VERSION ""

NS_ :

BS_:

BU_: XXX X

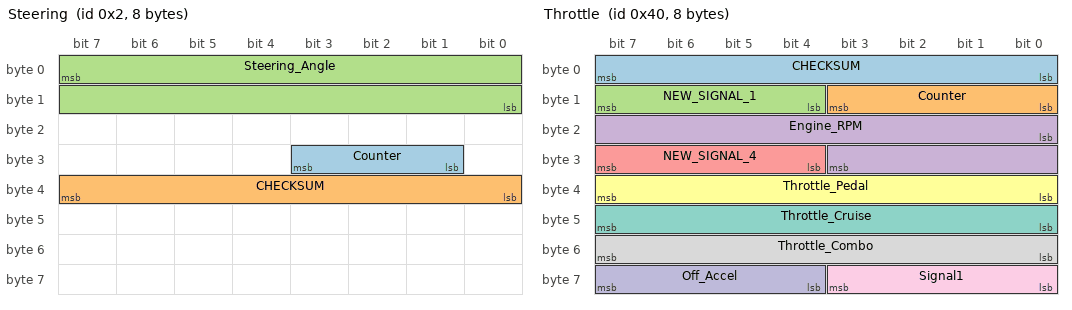
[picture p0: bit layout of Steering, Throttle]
BO_ 2 Steering: 8 XXX
 SG_ Counter : 25|3@1+ (1,0) [0|7] "" XXX
 SG_ CHECKSUM : 32|8@1+ (1,0) [0|255] "" XXX
 SG_ Steering_Angle : 7|16@0- (0.1,0) [0|65535] "" XXX

BO_ 64 Throttle: 8 XXX
 SG_ CHECKSUM : 0|8@1+ (1,0) [0|255] "" XXX
 SG_ Counter : 8|4@1+ (1,0) [0|255] "" XXX
 SG_ NEW_SIGNAL_1 : 12|4@1+ (1,0) [0|1] "" XXX
 SG_ Engine_RPM : 16|12@1+ (1,0) [0|255] "" XXX
 SG_ NEW_SIGNAL_4 : 28|4@1+ (1,0) [0|1] "" XXX
 SG_ Throttle_Pedal : 32|8@1+ (1,0) [0|255] "" XXX
 SG_ Throttle_Cruise : 40|8@1+ (1,0) [0|255] "" XXX
 SG_ Throttle_Combo : 48|8@1+ (1,0) [0|1] "" XXX
 SG_ Signal1 : 56|4@1+ (1,0) [0|255] "" XXX
 SG_ Off_Accel : 60|4@1+ (1,0) [0|7] "" XXX

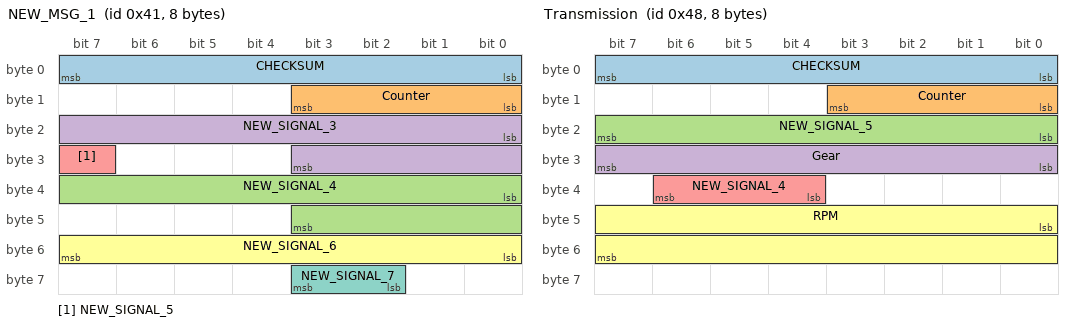
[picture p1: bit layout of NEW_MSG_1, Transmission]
BO_ 65 NEW_MSG_1: 8 XXX
 SG_ CHECKSUM : 0|8@1+ (1,0) [0|255] "" XXX
 SG_ Counter : 8|4@1+ (1,0) [0|15] "" XXX
 SG_ NEW_SIGNAL_4 : 32|12@1+ (1,0) [0|255] "" XXX
 SG_ NEW_SIGNAL_3 : 16|12@1+ (1,0) [0|1] "" XXX
 SG_ NEW_SIGNAL_5 : 31|1@0+ (1,0) [0|15] "" XXX
 SG_ NEW_SIGNAL_6 : 48|8@1+ (1,0) [0|63] "" XXX
 SG_ NEW_SIGNAL_7 : 59|2@0+ (1,0) [0|255] "" XXX

BO_ 72 Transmission: 8 XXX
 SG_ CHECKSUM : 0|8@1+ (1,0) [0|255] "" XXX
 SG_ Counter : 8|4@1+ (1,0) [0|15] "" XXX
 SG_ NEW_SIGNAL_5 : 16|8@1+ (1,0) [0|255] "" XXX
 SG_ Gear : 24|8@1+ (1,0) [0|255] "" XXX
 SG_ NEW_SIGNAL_4 : 38|3@0+ (1,0) [0|255] "" XXX
 SG_ RPM : 40|16@1+ (1,0) [0|255] "" XXX

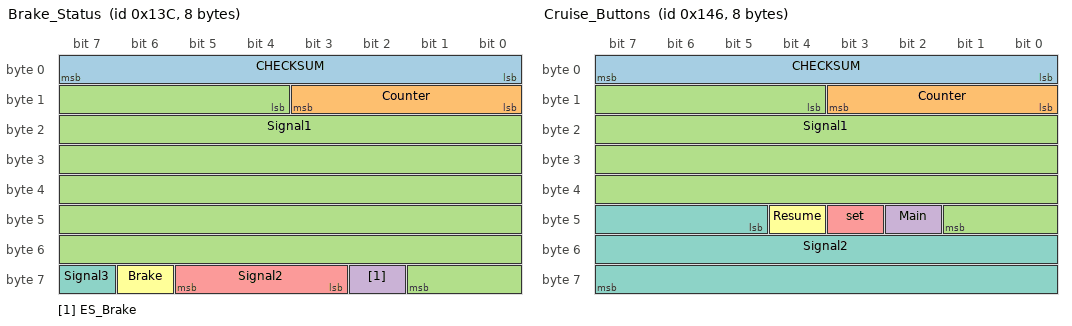
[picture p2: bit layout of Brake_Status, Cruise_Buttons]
BO_ 316 Brake_Status: 8 XXX
 SG_ CHECKSUM : 0|8@1+ (1,0) [0|1] "" XXX
 SG_ Counter : 8|4@1+ (1,0) [0|1] "" XXX
 SG_ Signal1 : 12|46@1+ (1,0) [0|1] "" XXX
 SG_ ES_Brake : 58|1@1+ (1,0) [0|1] "" XXX
 SG_ Signal2 : 59|3@1+ (1,0) [0|1] "" XXX
 SG_ Brake : 62|1@1+ (1,0) [0|1] "" XXX
 SG_ Signal3 : 63|1@1+ (1,0) [0|1] "" XXX

BO_ 326 Cruise_Buttons: 8 XXX
 SG_ CHECKSUM : 0|8@1+ (1,0) [0|255] "" XXX
 SG_ Counter : 8|4@1+ (1,0) [0|15] "" XXX
 SG_ Signal1 : 12|30@1+ (1,0) [0|1073741823] "" XXX
 SG_ Main : 42|1@1+ (1,0) [0|1] "" XXX
 SG_ set : 43|1@1+ (1,0) [0|1] "" XXX
 SG_ Resume : 44|1@1+ (1,0) [0|1] "" XXX
 SG_ Signal2 : 45|19@1+ (1,0) [0|524287] "" XXX

BO_ 315 G_Sensor: 8 XXX
 SG_ Longitudinal : 56|8@1- (-0.1,0) [0|255] "m/s2" XXX
 SG_ Lateral : 48|8@1- (-0.1,0) [0|255] "m/s2" XXX

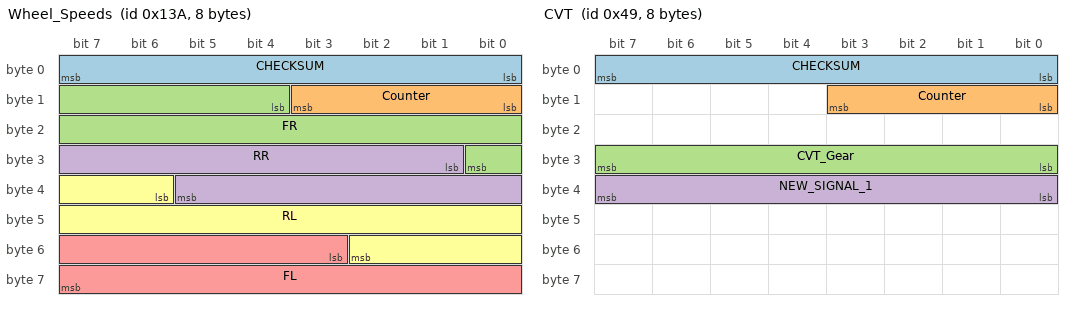
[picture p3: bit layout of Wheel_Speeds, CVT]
BO_ 314 Wheel_Speeds: 8 XXX
 SG_ CHECKSUM : 0|8@1+ (1,0) [0|255] "" XXX
 SG_ Counter : 8|4@1+ (1,0) [0|15] "" XXX
 SG_ FR : 12|13@1+ (0.057,0) [0|255] "kph" XXX
 SG_ RR : 25|13@1+ (0.057,0) [0|255] "kph" XXX
 SG_ FL : 51|13@1+ (0.057,0) [0|255] "kph" XXX
 SG_ RL : 38|13@1+ (0.057,0) [0|255] "kph" XXX

BO_ 73 CVT: 8 XXX
 SG_ CHECKSUM : 0|8@1+ (1,0) [0|255] "" XXX
 SG_ Counter : 8|4@1+ (1,0) [0|15] "" XXX
 SG_ CVT_Gear : 24|8@1+ (1,0) [0|127] "" XXX
 SG_ NEW_SIGNAL_1 : 32|8@1+ (1,0) [0|4095] "" XXX

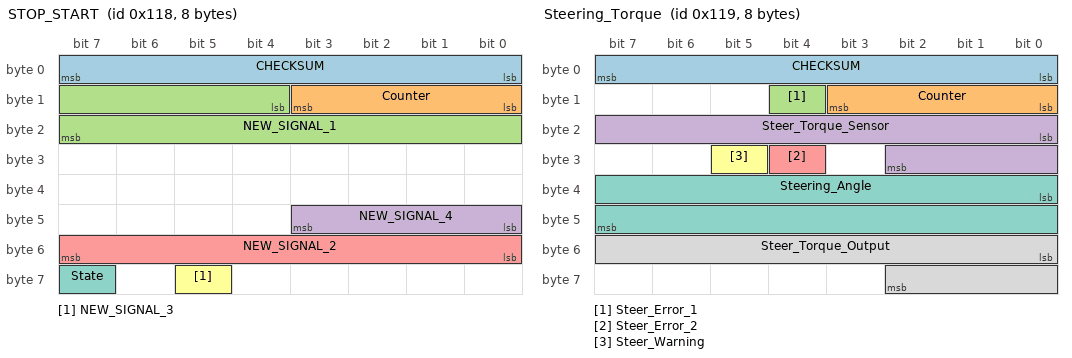
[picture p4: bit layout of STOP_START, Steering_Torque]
BO_ 280 STOP_START: 8 XXX
 SG_ CHECKSUM : 0|8@1+ (1,0) [0|1] "" XXX
 SG_ Counter : 8|4@1+ (1,0) [0|1] "" XXX
 SG_ NEW_SIGNAL_1 : 12|12@1- (1,0) [0|4095] "" XXX
 SG_ NEW_SIGNAL_4 : 40|4@1+ (1,0) [0|255] "" XXX
 SG_ NEW_SIGNAL_2 : 48|8@1- (1,0) [0|255] "" XXX
 SG_ NEW_SIGNAL_3 : 61|1@1+ (1,0) [0|7] "" XXX
 SG_ State : 63|1@1+ (1,0) [0|1] "" XXX

BO_ 281 Steering_Torque: 8 XXX
 SG_ CHECKSUM : 0|8@1+ (1,0) [0|3] "" XXX
 SG_ Counter : 8|4@1+ (1,0) [0|15] "" XXX
 SG_ Steer_Error_1 : 12|1@0+ (1,0) [0|7] "" XXX
 SG_ Steer_Torque_Sensor : 16|11@1- (-1,0) [0|3] "" XXX
 SG_ Steer_Error_2 : 28|1@1+ (1,0) [0|3] "" XXX
 SG_ Steer_Warning : 29|1@1+ (1,0) [0|1] "" XXX
 SG_ Steering_Angle : 32|16@1- (-0.0217,0) [0|255] "" X
 SG_ Steer_Torque_Output : 48|11@1- (-1,0) [0|31] "" XXX

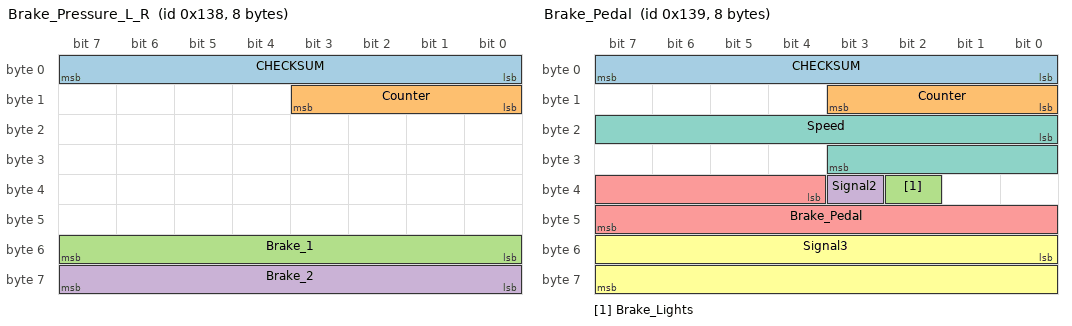
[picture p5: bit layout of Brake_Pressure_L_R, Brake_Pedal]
BO_ 312 Brake_Pressure_L_R: 8 XXX
 SG_ CHECKSUM : 0|8@1+ (1,0) [0|31] "" XXX
 SG_ Counter : 8|4@1+ (1,0) [0|3] "" XXX
 SG_ Brake_1 : 48|8@1+ (1,0) [0|255] "" XXX
 SG_ Brake_2 : 56|8@1+ (1,0) [0|255] "" XXX

BO_ 313 Brake_Pedal: 8 XXX
 SG_ CHECKSUM : 0|8@1+ (1,0) [0|1] "" XXX
 SG_ Counter : 8|4@1+ (1,0) [0|1] "" XXX
 SG_ Brake_Lights : 34|1@1+ (1,0) [0|7] "" XXX
 SG_ Signal2 : 35|1@1+ (1,0) [0|1] "" XXX
 SG_ Brake_Pedal : 36|12@1+ (1,0) [0|65535] "" XXX
 SG_ Signal3 : 48|16@1+ (1,0) [0|1] "" XXX
 SG_ Speed : 16|12@1+ (0.05625,0) [0|255] "kph" XXX

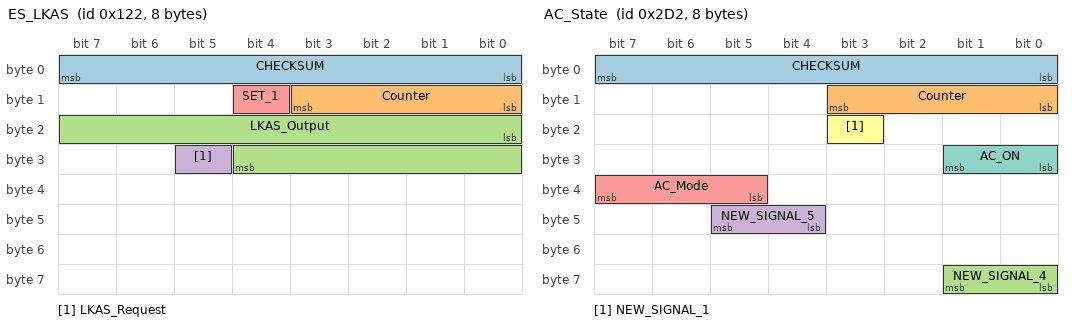
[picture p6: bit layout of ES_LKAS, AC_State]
BO_ 290 ES_LKAS: 8 XXX
 SG_ CHECKSUM : 0|8@1+ (1,0) [0|255] "" XXX
 SG_ Counter : 8|4@1+ (1,0) [0|15] "" XXX
 SG_ LKAS_Output : 16|13@1- (-1,0) [0|3] "" XXX
 SG_ LKAS_Request : 29|1@0+ (1,0) [0|3] "" XXX
 SG_ SET_1 : 12|1@0+ (1,0) [0|3] "" XXX

BO_ 722 AC_State: 8 XXX
 SG_ CHECKSUM : 0|8@1+ (1,0) [0|255] "" XXX
 SG_ Counter : 8|4@1+ (1,0) [0|15] "" XXX
 SG_ NEW_SIGNAL_4 : 56|2@1+ (1,0) [0|3] "" XXX
 SG_ NEW_SIGNAL_5 : 45|2@0+ (1,0) [0|3] "" XXX
 SG_ AC_Mode : 37|3@1+ (1,0) [0|1] "" XXX
 SG_ NEW_SIGNAL_1 : 19|1@1+ (1,0) [0|1] "" XXX
 SG_ AC_ON : 24|2@1+ (1,0) [0|1] "" XXX

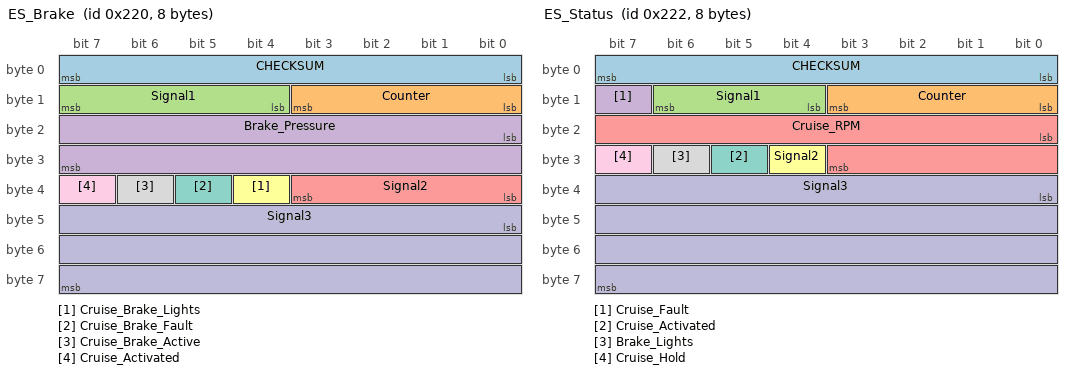
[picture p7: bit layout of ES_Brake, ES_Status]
BO_ 544 ES_Brake: 8 XXX
 SG_ CHECKSUM : 0|8@1+ (1,0) [0|255] "" XXX
 SG_ Counter : 8|4@1+ (1,0) [0|15] "" XXX
 SG_ Signal1 : 12|4@1+ (1,0) [0|1] "" XXX
 SG_ Brake_Pressure : 16|16@1+ (1,0) [0|255] "" XXX
 SG_ Signal2 : 32|4@1+ (1,0) [0|1] "" XXX
 SG_ Cruise_Brake_Lights : 36|1@1+ (1,0) [0|63] "" XXX
 SG_ Cruise_Brake_Fault : 37|1@1+ (1,0) [0|1] "" XXX
 SG_ Cruise_Brake_Active : 38|1@1+ (1,0) [0|1] "" XXX
 SG_ Cruise_Activated : 39|1@1+ (1,0) [0|1] "" XXX
 SG_ Signal3 : 40|24@1+ (1,0) [0|1] "" XXX

BO_ 545 ES_Distance: 8 XXX
 SG_ CHECKSUM : 0|8@1+ (1,0) [0|255] "" XXX
 SG_ Counter : 8|4@1+ (1,0) [0|15] "" XXX
 SG_ Signal1 : 12|3@1+ (1,0) [0|1] "" XXX
 SG_ Cruise_Fault : 15|1@1+ (1,0) [0|1] "" XXX
 SG_ Cruise_Throttle : 16|12@1+ (1,0) [0|15] "" XXX
 SG_ Signal2 : 28|4@1+ (1,0) [0|1] "" XXX
 SG_ Car_Follow : 32|1@1+ (1,0) [0|1] "" XXX
 SG_ Signal3 : 33|3@1+ (1,0) [0|1] "" XXX
 SG_ Cruise_Brake_Active : 36|1@1+ (1,0) [0|1] "" XXX
 SG_ Distance_Swap : 37|1@1+ (1,0) [0|15] "" XXX
 SG_ Cruise_EPB : 38|1@1+ (1,0) [0|1] "" XXX
 SG_ Signal4 : 39|1@0+ (1,0) [0|1] "" XXX
 SG_ Close_Distance : 40|8@1+ (1,0) [0|1] "" XXX
 SG_ Signal5 : 48|8@1+ (1,0) [0|1] "" XXX
 SG_ Cruise_Cancel : 56|1@1+ (1,0) [0|1] "" XXX
 SG_ Cruise_Set : 57|1@1+ (1,0) [0|1] "" XXX
 SG_ Cruise_Resume : 58|1@1+ (1,0) [0|1] "" XXX
 SG_ Signal6 : 59|5@1+ (1,0) [0|1] "" XXX

BO_ 546 ES_Status: 8 XXX
 SG_ CHECKSUM : 0|8@1+ (1,0) [0|255] "" XXX
 SG_ Counter : 8|4@1+ (1,0) [0|15] "" XXX
 SG_ Signal1 : 12|3@1+ (1,0) [0|1] "" XXX
 SG_ Cruise_Fault : 15|1@1+ (1,0) [0|1] "" XXX
 SG_ Cruise_RPM : 16|12@1+ (1,0) [0|255] "" XXX
 SG_ Signal2 : 28|1@0+ (1,0) [0|1] "" XXX
 SG_ Cruise_Activated : 29|1@0+ (1,0) [0|3] "" XXX
 SG_ Brake_Lights : 30|1@1+ (1,0) [0|3] "" XXX
 SG_ Cruise_Hold : 31|1@1+ (1,0) [0|1] "" XXX
 SG_ Signal3 : 32|32@1+ (1,0) [0|1] "" XXX

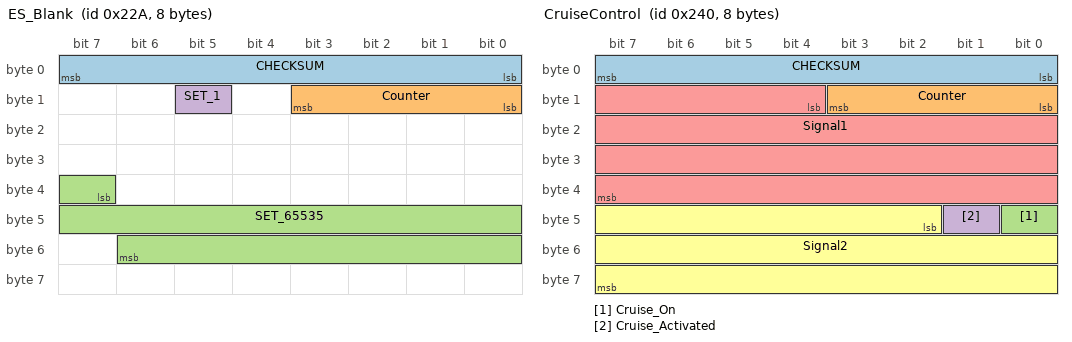
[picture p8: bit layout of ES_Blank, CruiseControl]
BO_ 554 ES_Blank: 8 XXX
 SG_ CHECKSUM : 0|8@1+ (1,0) [0|255] "" XXX
 SG_ Counter : 8|4@1+ (1,0) [0|15] "" XXX
 SG_ SET_65535 : 39|16@1+ (1,0) [0|16777215] "" XXX
 SG_ SET_1 : 13|1@1+ (1,0) [0|7] "" XXX

BO_ 557 NEW_MSG_14: 8 XXX
 SG_ CHECKSUM : 0|8@1+ (1,0) [0|255] "" XXX
 SG_ Counter : 8|4@1+ (1,0) [0|15] "" XXX

BO_ 576 CruiseControl: 8 XXX
 SG_ CHECKSUM : 0|8@1+ (1,0) [0|255] "" XXX
 SG_ Counter : 8|4@1+ (1,0) [0|15] "" XXX
 SG_ Cruise_On : 40|1@1+ (1,0) [0|3] "" XXX
 SG_ Cruise_Activated : 41|1@1+ (1,0) [0|3] "" XXX
 SG_ Signal1 : 12|28@1+ (1,0) [0|1] "" XXX
 SG_ Signal2 : 42|22@1+ (1,0) [0|3] "" XXX

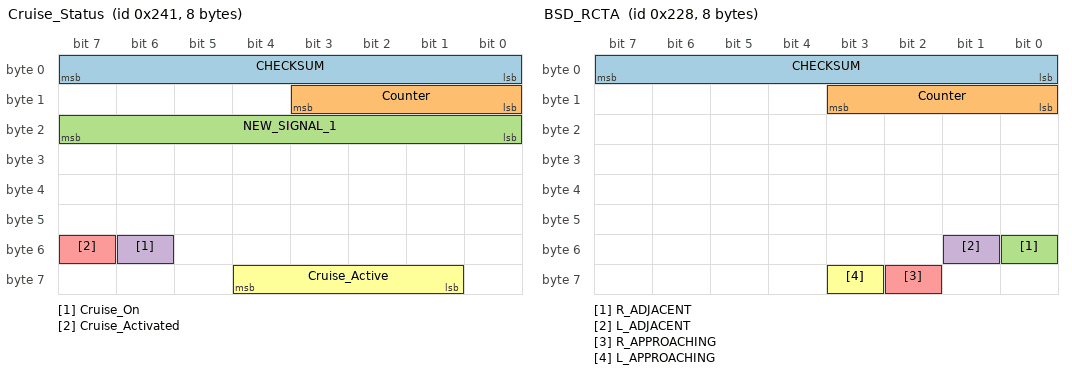
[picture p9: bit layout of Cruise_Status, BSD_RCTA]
BO_ 577 Cruise_Status: 8 XXX
 SG_ CHECKSUM : 0|8@1+ (1,0) [0|255] "" XXX
 SG_ Counter : 8|4@1+ (1,0) [0|15] "" XXX
 SG_ NEW_SIGNAL_1 : 16|8@1+ (1,0) [0|255] "" XXX
 SG_ Cruise_On : 54|1@1+ (1,0) [0|1] "" XXX
 SG_ Cruise_Activated : 55|1@1+ (1,0) [0|1] "" XXX
 SG_ Cruise_Active : 57|4@1+ (1,0) [0|1] "" XXX

BO_ 552 BSD_RCTA: 8 XXX
 SG_ CHECKSUM : 0|8@1+ (1,0) [0|255] "" XXX
 SG_ Counter : 8|4@1+ (1,0) [0|15] "" XXX
 SG_ R_ADJACENT : 48|1@1+ (1,0) [0|1] "" XXX
 SG_ L_ADJACENT : 49|1@1+ (1,0) [0|1] "" XXX
 SG_ R_APPROACHING : 58|1@1+ (1,0) [0|1] "" XXX
 SG_ L_APPROACHING : 59|1@1+ (1,0) [0|1] "" XXX

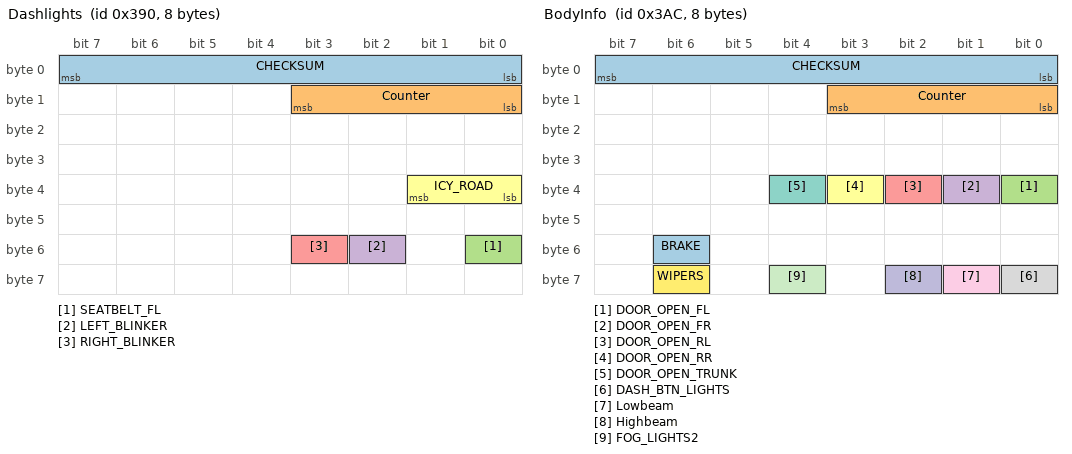
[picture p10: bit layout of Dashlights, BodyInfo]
BO_ 912 Dashlights: 8 XXX
 SG_ CHECKSUM : 0|8@1+ (1,0) [0|255] "" XXX
 SG_ Counter : 8|4@1+ (1,0) [0|15] "" XXX
 SG_ SEATBELT_FL : 48|1@1+ (1,0) [0|1] "" XXX
 SG_ LEFT_BLINKER : 50|1@1+ (1,0) [0|3] "" XXX
 SG_ RIGHT_BLINKER : 51|1@1+ (1,0) [0|1] "" XXX
 SG_ ICY_ROAD : 32|2@1+ (1,0) [0|3] "" XXX

BO_ 940 BodyInfo: 8 XXX
 SG_ CHECKSUM : 0|8@1+ (1,0) [0|1] "" XXX
 SG_ Counter : 8|4@1+ (1,0) [0|1] "" XXX
 SG_ DOOR_OPEN_FL : 32|1@1+ (1,0) [0|255] "" XXX
 SG_ DOOR_OPEN_FR : 33|1@1+ (1,0) [0|3] "" XXX
 SG_ DOOR_OPEN_RL : 34|1@1+ (1,0) [0|1] "" XXX
 SG_ DOOR_OPEN_RR : 35|1@1+ (1,0) [0|1] "" XXX
 SG_ DOOR_OPEN_TRUNK : 36|1@0+ (1,0) [0|1] "" XXX
 SG_ DASH_BTN_LIGHTS : 56|1@0+ (1,0) [0|1] "" XXX
 SG_ Lowbeam : 57|1@1+ (1,0) [0|3] "" XXX
 SG_ Highbeam : 58|1@1+ (1,0) [0|1] "" XXX
 SG_ FOG_LIGHTS2 : 60|1@1+ (1,0) [0|1] "" XXX
 SG_ WIPERS : 62|1@0+ (1,0) [0|1] "" XXX
 SG_ BRAKE : 54|1@1+ (1,0) [0|1] "" XXX

BO_ 801 ES_DashStatus: 8 XXX
 SG_ CHECKSUM : 0|8@1+ (1,0) [0|255] "" XXX
 SG_ Counter : 8|4@1+ (1,0) [0|7] "" XXX
 SG_ PCB_Off : 12|1@1+ (1,0) [0|1] "" XXX
 SG_ LDW_Off : 13|1@1+ (1,0) [0|1] "" XXX
 SG_ Signal1 : 14|10@1+ (1,0) [0|1] "" XXX
 SG_ Cruise_Soft_Disable : 24|1@1+ (1,0) [0|1] "" XXX
 SG_ Signal7 : 25|3@1+ (1,0) [0|1] "" XXX
 SG_ Cruise_Distance : 28|3@1+ (1,0) [0|3] "" XXX
 SG_ Signal2 : 31|1@1+ (1,0) [0|1] "" XXX
 SG_ Conventional_Cruise : 32|1@1+ (1,0) [0|1] "" XXX
 SG_ Signal3 : 33|2@1+ (1,0) [0|1] "" XXX
 SG_ Cruise_Disengaged : 35|1@1+ (1,0) [0|3] "" XXX
 SG_ Cruise_Activated : 36|1@1+ (1,0) [0|3] "" XXX
 SG_ Signal4 : 37|3@1+ (1,0) [0|1] "" XXX
 SG_ Cruise_Set_Speed : 40|8@1+ (1,0) [0|255] "" XXX
 SG_ Cruise_Fault : 48|1@1+ (1,0) [0|1] "" XXX
 SG_ Signal5 : 49|2@1+ (1,0) [0|3] "" XXX
 SG_ Brake_Lights : 51|1@1+ (1,0) [0|3] "" XXX
 SG_ Car_Follow : 52|1@1+ (1,0) [0|3] "" XXX
 SG_ Signal6 : 53|3@1+ (1,0) [0|1] "" XXX
 SG_ Far_Distance : 56|4@1+ (1,0) [0|15] "" XXX
 SG_ Cruise_State : 60|4@1+ (1,0) [0|15] "" XXX

BO_ 802 ES_LKAS_State: 8 XXX
 SG_ CHECKSUM : 0|8@1+ (1,0) [0|255] "" XXX
 SG_ Counter : 8|4@1+ (1,0) [0|15] "" XXX
 SG_ Keep_Hands_On_Wheel : 12|1@1+ (1,0) [0|1] "" XXX
 SG_ Empty_Box : 13|1@1+ (1,0) [0|1] "" XXX
 SG_ Signal1 : 14|3@1+ (1,0) [0|7] "" XXX
 SG_ LKAS_ACTIVE : 17|1@1+ (1,0) [0|3] "" XXX
 SG_ Signal2 : 18|5@1+ (1,0) [0|7] "" XXX
 SG_ Backward_Speed_Limit_Menu : 23|1@1+ (1,0) [0|1] "" XXX
 SG_ LKAS_ENABLE_3 : 24|1@1+ (1,0) [0|1] "" XXX
 SG_ LKAS_Left_Line_Light_Blink : 25|1@1+ (1,0) [0|1] "" XXX
 SG_ LKAS_ENABLE_2 : 26|1@1+ (1,0) [0|1] "" XXX
 SG_ LKAS_Right_Line_Light_Blink : 27|1@1+ (1,0) [0|1] "" XXX
 SG_ LKAS_Left_Line_Visible : 28|1@1+ (1,0) [0|1] "" XXX
 SG_ LKAS_Left_Line_Green : 29|1@1+ (1,0) [0|1] "" XXX
 SG_ LKAS_Right_Line_Visible : 30|1@1+ (1,0) [0|1] "" XXX
 SG_ LKAS_Right_Line_Green : 31|1@1+ (1,0) [0|1] "" XXX
 SG_ LKAS_Alert : 32|4@1+ (1,0) [0|15] "" XXX
 SG_ Signal5 : 37|27@1+ (1,0) [0|1] "" XXX
 SG_ LKAS_Off : 36|1@1+ (1,0) [0|1] "" XXX

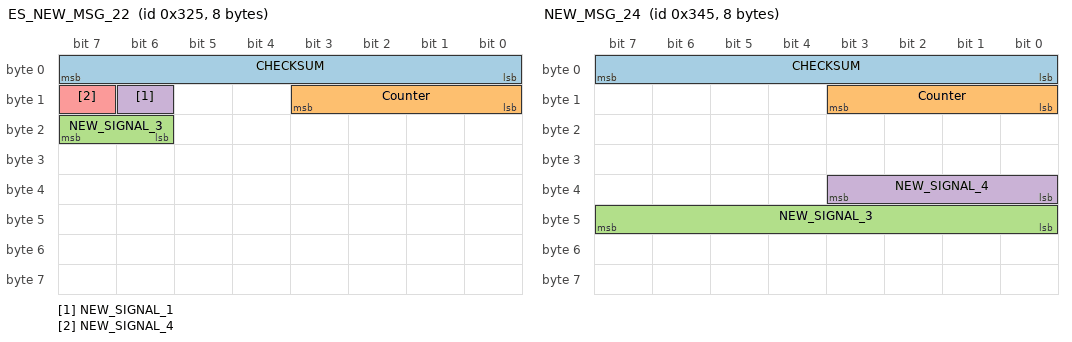
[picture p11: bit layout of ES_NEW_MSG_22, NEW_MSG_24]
BO_ 805 ES_NEW_MSG_22: 8 XXX
 SG_ CHECKSUM : 0|8@1+ (1,0) [0|255] "" XXX
 SG_ Counter : 8|4@1+ (1,0) [0|15] "" XXX
 SG_ NEW_SIGNAL_3 : 22|2@1+ (1,0) [0|3] "" XXX
 SG_ NEW_SIGNAL_1 : 14|1@1+ (1,0) [0|3] "" XXX
 SG_ NEW_SIGNAL_4 : 15|1@1+ (1,0) [0|3] "" XXX

BO_ 808 NEW_MSG_23: 8 XXX
 SG_ CHECKSUM : 0|8@1+ (1,0) [0|255] "" XXX
 SG_ Counter : 8|4@1+ (1,0) [0|15] "" XXX

BO_ 837 NEW_MSG_24: 8 XXX
 SG_ CHECKSUM : 0|8@1+ (1,0) [0|255] "" XXX
 SG_ Counter : 8|4@1+ (1,0) [0|15] "" XXX
 SG_ NEW_SIGNAL_3 : 40|8@1+ (1,0) [0|255] "" XXX
 SG_ NEW_SIGNAL_4 : 32|4@1+ (1,0) [0|15] "" XXX

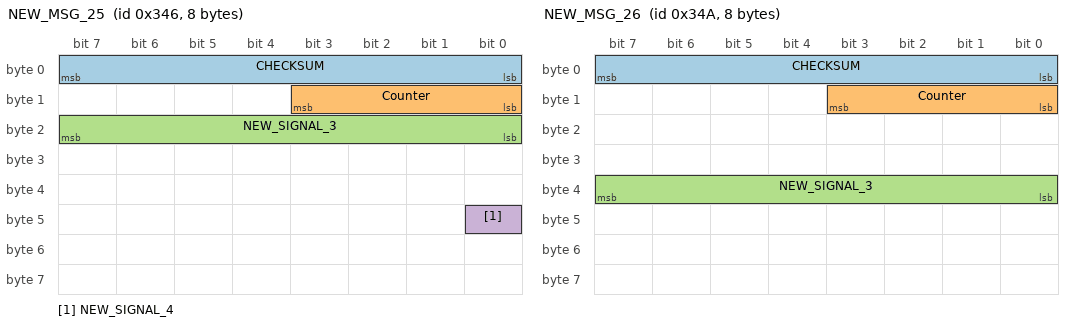
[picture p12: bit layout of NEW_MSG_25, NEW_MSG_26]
BO_ 838 NEW_MSG_25: 8 XXX
 SG_ CHECKSUM : 0|8@1+ (1,0) [0|255] "" XXX
 SG_ Counter : 8|4@1+ (1,0) [0|15] "" XXX
 SG_ NEW_SIGNAL_3 : 16|8@1+ (1,0) [0|255] "" XXX
 SG_ NEW_SIGNAL_4 : 40|1@1+ (1,0) [0|3] "" XXX

BO_ 842 NEW_MSG_26: 8 XXX
 SG_ CHECKSUM : 0|8@1+ (1,0) [0|255] "" XXX
 SG_ Counter : 8|4@1+ (1,0) [0|15] "" XXX
 SG_ NEW_SIGNAL_3 : 32|8@1+ (1,0) [0|255] "" XXX

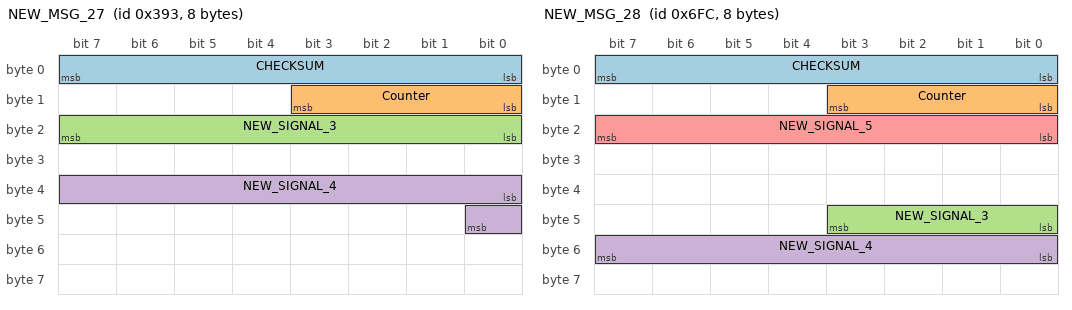
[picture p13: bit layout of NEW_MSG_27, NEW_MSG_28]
BO_ 915 NEW_MSG_27: 8 XXX
 SG_ CHECKSUM : 0|8@1+ (1,0) [0|255] "" XXX
 SG_ Counter : 8|4@1+ (1,0) [0|15] "" XXX
 SG_ NEW_SIGNAL_3 : 16|8@1+ (1,0) [0|255] "" XXX
 SG_ NEW_SIGNAL_4 : 32|9@1+ (1,0) [0|255] "" XXX

BO_ 1788 NEW_MSG_28: 8 XXX
 SG_ CHECKSUM : 0|8@1+ (1,0) [0|255] "" XXX
 SG_ Counter : 8|4@1+ (1,0) [0|15] "" XXX
 SG_ NEW_SIGNAL_3 : 40|4@1+ (1,0) [0|15] "" XXX
 SG_ NEW_SIGNAL_4 : 48|8@1+ (1,0) [0|255] "" XXX
 SG_ NEW_SIGNAL_5 : 16|8@1+ (1,0) [0|255] "" XXX

BO_ 816 NEW_MSG_29: 8 XXX
 SG_ CHECKSUM : 0|8@1+ (1,0) [0|255] "" XXX
 SG_ Counter : 8|4@1+ (1,0) [0|15] "" XXX

BO_ 826 NEW_MSG_30: 8 XXX
 SG_ CHECKSUM : 0|8@1+ (1,0) [0|255] "" XXX
 SG_ Counter : 8|4@1+ (1,0) [0|15] "" XXX

BO_ 839 NEW_MSG_31: 8 XXX
 SG_ CHECKSUM : 0|8@1+ (1,0) [0|255] "" XXX
 SG_ Counter : 8|4@1+ (1,0) [0|15] "" XXX

BO_ 2015 NEW_MSG_32: 8 XXX
 SG_ NEW_SIGNAL_2 : 16|8@1+ (1,0) [0|255] "" XXX

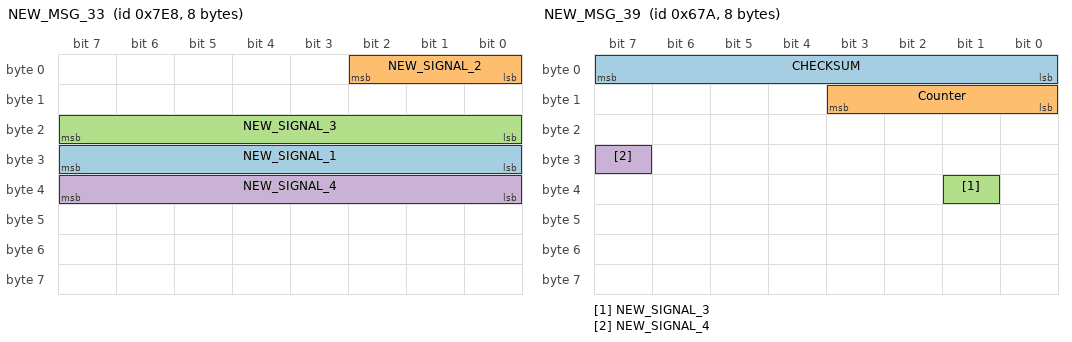
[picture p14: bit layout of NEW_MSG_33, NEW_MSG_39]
BO_ 2024 NEW_MSG_33: 8 XXX
 SG_ NEW_SIGNAL_1 : 24|8@1+ (1,0) [0|255] "" XXX
 SG_ NEW_SIGNAL_2 : 0|3@1+ (1,0) [0|15] "" XXX
 SG_ NEW_SIGNAL_3 : 16|8@1+ (1,0) [0|255] "" XXX
 SG_ NEW_SIGNAL_4 : 32|8@1+ (1,0) [0|255] "" XXX

BO_ 1614 NEW_MSG_34: 8 XXX
 SG_ CHECKSUM : 0|8@1+ (1,0) [0|255] "" XXX
 SG_ Counter : 8|4@1+ (1,0) [0|15] "" XXX

BO_ 1617 NEW_MSG_35: 8 XXX
 SG_ CHECKSUM : 0|8@1+ (1,0) [0|255] "" XXX
 SG_ Counter : 8|4@1+ (1,0) [0|15] "" XXX

BO_ 1632 NEW_MSG_36: 8 XXX
 SG_ NEW_SIGNAL_1 : 55|16@0+ (1,0) [0|255] "" XXX

BO_ 1650 NEW_MSG_37: 8 XXX
 SG_ CHECKSUM : 0|8@1+ (1,0) [0|255] "" XXX
 SG_ Counter : 8|4@1+ (1,0) [0|15] "" XXX

BO_ 1657 NEW_MSG_38: 8 XXX
 SG_ CHECKSUM : 0|8@1+ (1,0) [0|255] "" XXX
 SG_ Counter : 8|4@1+ (1,0) [0|15] "" XXX

BO_ 1658 NEW_MSG_39: 8 XXX
 SG_ CHECKSUM : 0|8@1+ (1,0) [0|255] "" XXX
 SG_ Counter : 8|4@1+ (1,0) [0|15] "" XXX
 SG_ NEW_SIGNAL_3 : 33|1@1+ (1,0) [0|3] "" XXX
 SG_ NEW_SIGNAL_4 : 31|1@0+ (1,0) [0|3] "" XXX

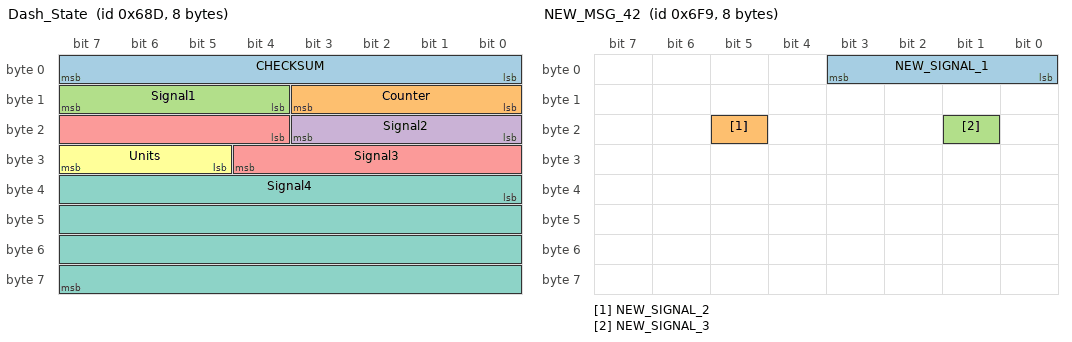
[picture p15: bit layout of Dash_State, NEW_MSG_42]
BO_ 1677 Dash_State: 8 XXX
 SG_ CHECKSUM : 0|8@1+ (1,0) [0|255] "" XXX
 SG_ Counter : 8|4@1+ (1,0) [0|15] "" XXX
 SG_ Signal1 : 12|4@1+ (1,0) [0|1] "" XXX
 SG_ Signal2 : 16|4@1+ (1,0) [0|15] "" XXX
 SG_ Signal3 : 20|9@1+ (1,0) [0|1] "" XXX
 SG_ Units : 29|3@1+ (1,0) [0|7] "" XXX
 SG_ Signal4 : 32|32@1+ (1,0) [0|1] "" XXX

BO_ 1743 NEW_MSG_41: 8 XXX
 SG_ CHECKSUM : 0|8@1+ (1,0) [0|255] "" XXX
 SG_ Counter : 8|4@1+ (1,0) [0|15] "" XXX

BO_ 1785 NEW_MSG_42: 8 XXX
 SG_ NEW_SIGNAL_1 : 0|4@1+ (1,0) [0|255] "" XXX
 SG_ NEW_SIGNAL_2 : 21|1@1+ (1,0) [0|31] "" XXX
 SG_ NEW_SIGNAL_3 : 17|1@1+ (1,0) [0|7] "" XXX

BO_ 1759 NEW_MSG_43: 8 XXX
 SG_ NEW_SIGNAL_1 : 17|1@1+ (1,0) [0|3] "" XXX

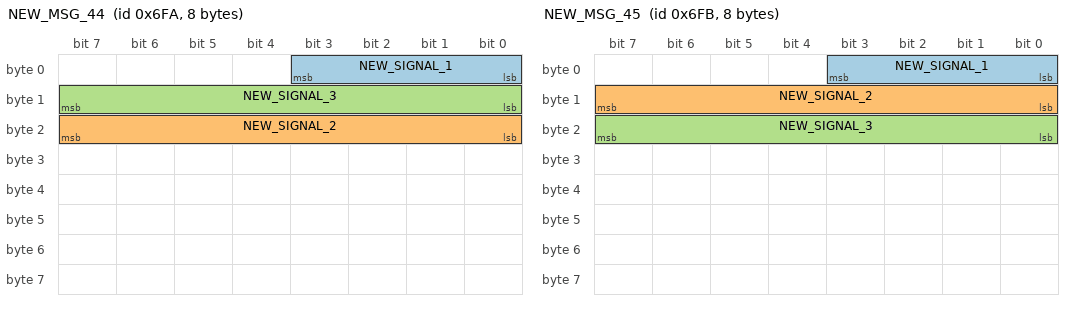
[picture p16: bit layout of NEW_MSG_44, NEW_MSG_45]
BO_ 1786 NEW_MSG_44: 8 XXX
 SG_ NEW_SIGNAL_1 : 0|4@1+ (1,0) [0|15] "" XXX
 SG_ NEW_SIGNAL_2 : 16|8@1+ (1,0) [0|255] "" XXX
 SG_ NEW_SIGNAL_3 : 8|8@1+ (1,0) [0|15] "" XXX

BO_ 1787 NEW_MSG_45: 8 XXX
 SG_ NEW_SIGNAL_1 : 0|4@1+ (1,0) [0|15] "" XXX
 SG_ NEW_SIGNAL_2 : 8|8@1+ (1,0) [0|255] "" XXX
 SG_ NEW_SIGNAL_3 : 16|8@1+ (1,0) [0|255] "" XXX

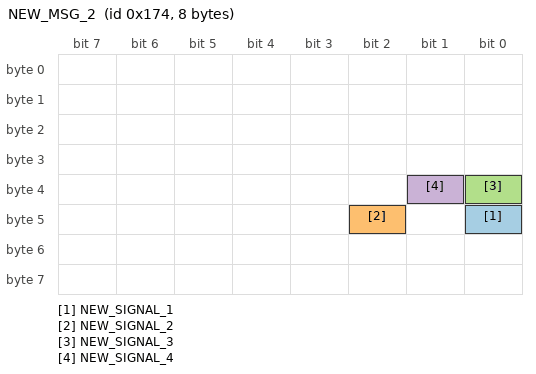
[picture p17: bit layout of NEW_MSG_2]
BO_ 372 NEW_MSG_2: 8 XXX
 SG_ NEW_SIGNAL_1 : 40|1@0+ (1,0) [0|1] "" XXX
 SG_ NEW_SIGNAL_2 : 42|1@0+ (1,0) [0|1] "" XXX
 SG_ NEW_SIGNAL_3 : 32|1@0+ (1,0) [0|1] "" XXX
 SG_ NEW_SIGNAL_4 : 33|1@0+ (1,0) [0|1] "" XXX

BO_ 289 NEW_MSG_3: 8 XXX
 SG_ Counter : 8|4@1+ (1,0) [0|1] "" XXX

CM_ SG_ 64 Throttle_Combo "Throttle Cruise + Pedal";
CM_ SG_ 313 Brake_Lights "Driver or Cruise Brake on";
CM_ SG_ 544 Cruise_Brake_Lights "1 = switch on brake lights";
CM_ SG_ 545 Cruise_Throttle "RPM-like output signal";
CM_ SG_ 545 Distance_Swap "Switch from Close to Far distance";
CM_ SG_ 545 Cruise_EPB "1 = set Electric Parking Brake";
CM_ SG_ 546 Cruise_RPM "ES RPM output for ECM and TCM";
CM_ SG_ 546 Signal3 "0 when cruise_activated = 1";
CM_ SG_ 912 ICY_ROAD "1 = DASHLIGHT ON, 2 = WARNING, 3 = OFF";
CM_ SG_ 940 Highbeam "01 = low beam, 11 = high beam";
CM_ SG_ 940 FOG_LIGHTS2 "yellow fog light in the dash";
CM_ SG_ 801 PCB_Off "Pre-Collision Braking off";
CM_ SG_ 801 Cruise_Soft_Disable "Eyesight soft disable (eg direct sunlight)";
CM_ SG_ 801 Brake_Lights "Driver or Cruise brake on";
CM_ SG_ 801 Far_Distance "1=0-5m, 2=5-10m, 3=10-15m, 4=15-20m, 5=20-25m, 6=25-30m, 7=30-35m, 8=35-40m, 9=40-45m, 10=45-50m, 11=50-55m, 12=55-60m, 13=60-65m, 14=65-70m, 15=75m+";
CM_ SG_ 801 Cruise_State "0 = Normal, 1 = Hold+User Brake, 2 = Ready, 3 = Hold";
CM_ SG_ 802 LKAS_Alert "1 = FCW_Cont_Beep, 2 = FCW_Repeated_Beep, 3 = Throttle_Management_Activated_Warning, 4 = Throttle_Management_Activated_Alert, 8 = Traffic_Light_Ahead, 9 = Apply_Brake_to_Hold Position, 11 = LDW_Right, 12 = LDW_Left, 13 = Stay_Alert, 14 = Lead_Vehicle_Start_Alert";
CM_ SG_ 805 NEW_SIGNAL_3 "always 3";
CM_ SG_ 805 NEW_SIGNAL_4 "always 1";
CM_ SG_ 1677 Signal2 "Counter 0-15 with ~5sec steps, paused when brake is pressed, Signal3 += 1 when Signal2 = 15";
CM_ SG_ 1677 Units "AU/EU: 1 = imperial, 4 = metric US: 3 = imperial?";
VAL_ 72 Gear 2 "N" 3 "R" 4 "P" 121 "D" 137 "1" 145 "2" 153 "3" 161 "4" 169 "5" 177 "6" ;
